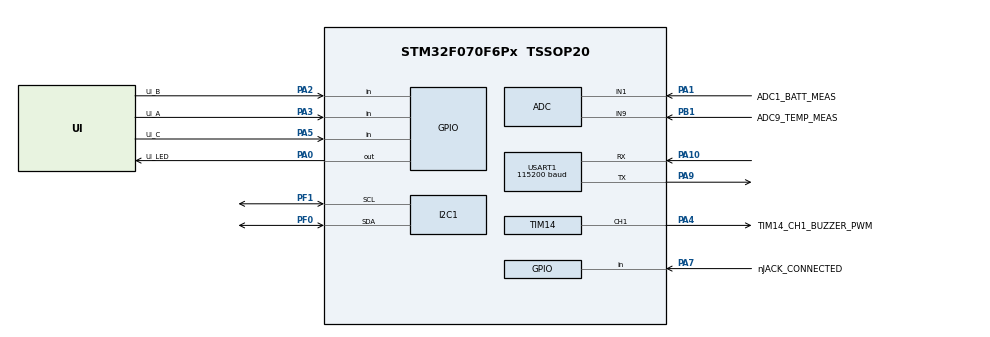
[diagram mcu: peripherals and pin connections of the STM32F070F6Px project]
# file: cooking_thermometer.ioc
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Mcu.Family=STM32F0
Mcu.Name=STM32F070F6Px
Mcu.Package=TSSOP20
NVIC.TIM1_BRK_UP_TRG_COM_IRQn=true\:3\:0\:false\:false\:true\:false\:true\:true
NVIC.TimeBase=TIM1_BRK_UP_TRG_COM_IRQn
NVIC.TimeBaseIP=TIM1
PA0.GPIO_Label=UI_LED
PA0.Signal=GPIO_Output
PA1.GPIO_Label=ADC1_BATT_MEAS
PA1.Mode=IN1
PA1.Signal=ADC_IN1
PA10.Mode=Asynchronous
PA10.Signal=USART1_RX
PA13.Mode=Serial_Wire
PA13.Signal=SYS_SWDIO
PA14.Mode=Serial_Wire
PA14.Signal=SYS_SWCLK
PA2.GPIO_Label=UI_B
PA2.GPIO_PuPd=GPIO_PULLDOWN
PA2.Signal=GPIO_Input
PA3.GPIO_Label=UI_A
PA3.GPIO_PuPd=GPIO_PULLDOWN
PA3.Signal=GPIO_Input
PA4.GPIO_Label=TIM14_CH1_BUZZER_PWM
PA4.Signal=S_TIM14_CH1
PA5.GPIO_Label=UI_C
PA5.GPIO_PuPd=GPIO_PULLDOWN
PA5.Signal=GPIO_Input
PA7.GPIO_Label=nJACK_CONNECTED
PA7.GPIO_PuPd=GPIO_PULLUP
PA7.Signal=GPIO_Input
PA9.Mode=Asynchronous
PA9.Signal=USART1_TX
PB1.GPIO_Label=ADC9_TEMP_MEAS
PB1.Mode=IN9
PB1.Signal=ADC_IN9
PF0-OSC_IN.Mode=I2C
PF0-OSC_IN.Signal=I2C1_SDA
PF1-OSC_OUT.Mode=I2C
PF1-OSC_OUT.Signal=I2C1_SCL
ProjectManager.HeapSize=0x200
ProjectManager.StackSize=0x400
ProjectManager.TargetToolchain=CMake
SH.S_TIM14_CH1.0=TIM14_CH1,PWM Generation1 CH1
TIM14.Channel=TIM_CHANNEL_1
TIM14.Period=1000
TIM14.Prescaler=8
TIM14.Pulse=500
USART1.BaudRate=115200
USART1.VirtualMode=VM_ASYNC
VP_SYS_VS_tim1.Mode=TIM1
VP_TIM14_VS_ClockSourceINT.Mode=Enable_Timer
board=custom

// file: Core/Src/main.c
/* USER CODE BEGIN Header */
/**
  ******************************************************************************
  * @file           : main.c
  * @brief          : Main program body
  ******************************************************************************
  * @attention
  *
  * Copyright (c) 2024 STMicroelectronics.
  * All rights reserved.
  *
  * This software is licensed under terms that can be found in the LICENSE file
  * in the root directory of this software component.
  * If no LICENSE file comes with this software, it is provided AS-IS.
  *
  ******************************************************************************
  */
/* USER CODE END Header */
#include "main.h"
#include "adc.h"
#include "i2c.h"
#include "tim.h"
#include "usart.h"
#include "gpio.h"

/* USER CODE BEGIN Includes */

#include "ssd1306.h"
#include "fonts.h"

/* USER CODE END Includes */

void SystemClock_Config(void);

int main(void)
{

  /* MCU Configuration--------------------------------------------------------*/

  /* Reset of all peripherals, Initializes the Flash interface and the Systick. */
  HAL_Init();

  /* Configure the system clock */
  SystemClock_Config();

  /* Initialize all configured peripherals */
  MX_GPIO_Init();
  MX_ADC_Init();
  MX_I2C1_Init();
  MX_USART1_UART_Init();
  MX_TIM14_Init();
  /* USER CODE BEGIN 2 */

  // Init lcd using one of the stm32HAL i2c typedefs
  if (ssd1306_Init(&hi2c1) != 0) {
    Error_Handler();
  }
  HAL_Delay(1000);

  ssd1306_Fill(Black);
  ssd1306_UpdateScreen(&hi2c1);

  HAL_Delay(1000);

  // Write data to local screenbuffer
  // ssd1306_SetCursor(0, 0);
  // ssd1306_WriteString("ssd1306", Font_7x10, White);

  // ssd1306_SetCursor(0, 16);
  // ssd1306_WriteString("4ilo", Font_7x10, White);

  // for (uint8_t y = 0; y < 64; y++) {
  //   for (uint8_t x=(y*2); x<((y+1)*2); x++) {
  //       ssd1306_DrawPixel(x, y, White);
  //   }
  // }

  // for (uint8_t y = 0; y < 32; y += 2) {
  //   for (uint8_t x=((y*4)+4); x<(((y+1)*4)+4); x++) {
  //       ssd1306_DrawPixel(x, y + 32, White);
  //   }
  // }

  // for (uint8_t x = 0; x < 128; x++) {
  //   ssd1306_DrawPixel(x, 63, White);
  // }

  ssd1306_SetCursor(0, 0);
  // ssd1306_WriteChar('8', Font_11x18, White);
  ssd1306_WriteString("Andreas", Font_16x26, White);
  ssd1306_SetCursor(0, 32);
  ssd1306_WriteString("Pettersson", Font_16x26, White);

  // for (uint8_t y=0; y<8; y++) {
  // }

  // Copy all data from local screenbuffer to the screen
  ssd1306_UpdateScreen(&hi2c1);

  /* USER CODE END 2 */

  /* Infinite loop */
  while (1)
  {

    HAL_GPIO_TogglePin(UI_LED_GPIO_Port, UI_LED_Pin);
    HAL_Delay(1000);

  }
}

void SystemClock_Config(void)
{
  RCC_OscInitTypeDef RCC_OscInitStruct = {0};
  RCC_ClkInitTypeDef RCC_ClkInitStruct = {0};
  RCC_PeriphCLKInitTypeDef PeriphClkInit = {0};

  /** Initializes the RCC Oscillators according to the specified parameters
  * in the RCC_OscInitTypeDef structure.
  */
  RCC_OscInitStruct.OscillatorType = RCC_OSCILLATORTYPE_HSI|RCC_OSCILLATORTYPE_HSI14;
  RCC_OscInitStruct.HSIState = RCC_HSI_ON;
  RCC_OscInitStruct.HSI14State = RCC_HSI14_ON;
  RCC_OscInitStruct.HSICalibrationValue = RCC_HSICALIBRATION_DEFAULT;
  RCC_OscInitStruct.HSI14CalibrationValue = 16;
  RCC_OscInitStruct.PLL.PLLState = RCC_PLL_NONE;
  if (HAL_RCC_OscConfig(&RCC_OscInitStruct) != HAL_OK)
  {
    Error_Handler();
  }

  /** Initializes the CPU, AHB and APB buses clocks
  */
  RCC_ClkInitStruct.ClockType = RCC_CLOCKTYPE_HCLK|RCC_CLOCKTYPE_SYSCLK
                              |RCC_CLOCKTYPE_PCLK1;
  RCC_ClkInitStruct.SYSCLKSource = RCC_SYSCLKSOURCE_HSI;
  RCC_ClkInitStruct.AHBCLKDivider = RCC_SYSCLK_DIV1;
  RCC_ClkInitStruct.APB1CLKDivider = RCC_HCLK_DIV1;

  if (HAL_RCC_ClockConfig(&RCC_ClkInitStruct, FLASH_LATENCY_0) != HAL_OK)
  {
    Error_Handler();
  }
  PeriphClkInit.PeriphClockSelection = RCC_PERIPHCLK_USART1|RCC_PERIPHCLK_I2C1;
  PeriphClkInit.Usart1ClockSelection = RCC_USART1CLKSOURCE_PCLK1;
  PeriphClkInit.I2c1ClockSelection = RCC_I2C1CLKSOURCE_HSI;
  if (HAL_RCCEx_PeriphCLKConfig(&PeriphClkInit) != HAL_OK)
  {
    Error_Handler();
  }
}

void HAL_TIM_PeriodElapsedCallback(TIM_HandleTypeDef *htim)
{
  if (htim->Instance == TIM1) {
    HAL_IncTick();
  }
}

void Error_Handler(void)
{
  __disable_irq();
  while (1)
  {
  }
}
